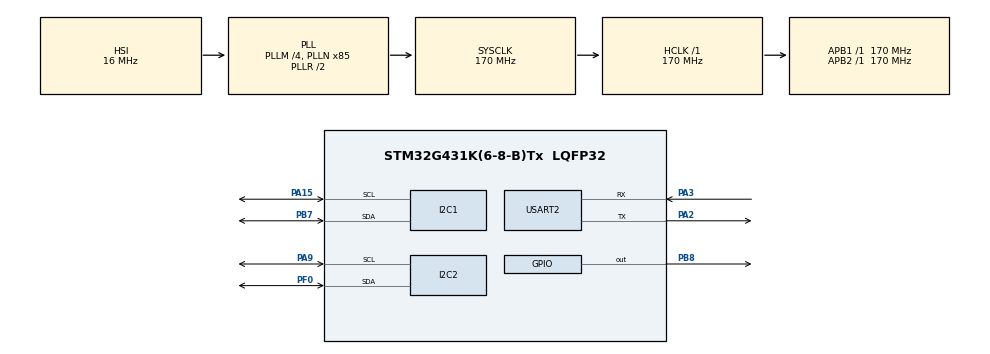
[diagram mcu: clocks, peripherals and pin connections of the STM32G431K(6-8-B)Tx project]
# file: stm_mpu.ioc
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I2C1.Timing=0x40B285C2
I2C2.Timing=0x40B285C2
Mcu.Family=STM32G4
Mcu.Name=STM32G431K(6-8-B)Tx
Mcu.Package=LQFP32
NUCLEO-G431KB.LD2=true
NUCLEO-G431KB.VCP=true
NVIC.PriorityGroup=NVIC_PRIORITYGROUP_4
PA13.GPIO_Label=T_SWDIO
PA13.Signal=SYS_JTMS-SWDIO
PA14.GPIO_Label=T_SWCLK
PA14.Signal=SYS_JTCK-SWCLK
PA15.Mode=I2C
PA15.Signal=I2C1_SCL
PA2.Mode=Asynchronous
PA2.Signal=USART2_TX
PA3.Mode=Asynchronous
PA3.Signal=USART2_RX
PA9.Mode=I2C
PA9.Signal=I2C2_SCL
PB3.GPIO_Label=T_SWO
PB3.Signal=SYS_JTDO-SWO
PB7.Mode=I2C
PB7.Signal=I2C1_SDA
PB8-BOOT0.Signal=GPIO_Output
PF0-OSC_IN.Mode=I2C
PF0-OSC_IN.Signal=I2C2_SDA
ProjectManager.HeapSize=0x200
ProjectManager.StackSize=0x400
ProjectManager.TargetToolchain=STM32CubeIDE
RCC.ADC12Freq_Value=170000000
RCC.AHBFreq_Value=170000000
RCC.APB1Freq_Value=170000000
RCC.APB1TimFreq_Value=170000000
RCC.APB2Freq_Value=170000000
RCC.APB2TimFreq_Value=170000000
RCC.CortexFreq_Value=170000000
RCC.EXTERNAL_CLOCK_VALUE=12288000
RCC.HCLKFreq_Value=170000000
RCC.HSE_VALUE=8000000
RCC.HSI48_VALUE=48000000
RCC.HSI_VALUE=16000000
RCC.LSE_VALUE=32768
RCC.PLLM=RCC_PLLM_DIV4
RCC.PLLN=85
RCC.SYSCLKFreq_VALUE=170000000
RCC.SYSCLKSource=RCC_SYSCLKSOURCE_PLLCLK
RCC.USBFreq_Value=170000000
RCC.VCOOutputFreq_Value=340000000
USART2.VirtualMode-Asynchronous=VM_ASYNC
VP_NUCLEO-G431KB_VS_BSP_COMMON.Mode=COMMON
VP_SYS_VS_DBSignals.Mode=DisableDeadBatterySignals
board=NUCLEO-G431KB

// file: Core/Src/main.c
/* USER CODE BEGIN Header */
/**
  ******************************************************************************
  * @file           : main.c
  * @brief          : Main program body
  ******************************************************************************
  * @attention
  *
  * Copyright (c) 2025 STMicroelectronics.
  * All rights reserved.
  *
  * This software is licensed under terms that can be found in the LICENSE file
  * in the root directory of this software component.
  * If no LICENSE file comes with this software, it is provided AS-IS.
  *
  ******************************************************************************
  */
/* USER CODE END Header */
#include "main.h"

/* USER CODE BEGIN Includes */
#include<MPU6050.h>
/* USER CODE END Includes */

I2C_HandleTypeDef hi2c1;
I2C_HandleTypeDef hi2c2;

UART_HandleTypeDef huart2;

void SystemClock_Config(void);
static void MX_GPIO_Init(void);
static void MX_I2C1_Init(void);
static void MX_I2C2_Init(void);
static void MX_USART2_UART_Init(void);

int main(void)
{

  /* MCU Configuration--------------------------------------------------------*/

  /* Reset of all peripherals, Initializes the Flash interface and the Systick. */
  HAL_Init();

  /* Configure the system clock */
  SystemClock_Config();

  /* Initialize all configured peripherals */
  MX_GPIO_Init();
  MX_I2C1_Init();
  MX_I2C2_Init();
  MX_USART2_UART_Init();

  /* Initialize leds */
  BSP_LED_Init(LED_GREEN);

  MPU6050_Initialization();

  /* Infinite loop */
  while (1)
  {
	    char buffer[100];  // Buffer to hold the formatted string
		MPU6050_ProcessData(&MPU6050);

	    // Format the data into a string
	    snprintf(buffer, sizeof(buffer), "%d, %d, %d\n",
	    		MPU6050.acc_x_raw, MPU6050.acc_y_raw, MPU6050.acc_z_raw);

	    // Send the string over UART
	    HAL_UART_Transmit(&huart2, (uint8_t*)buffer, strlen(buffer), HAL_MAX_DELAY);
	    HAL_Delay(50);
  }
}

void SystemClock_Config(void)
{
  RCC_OscInitTypeDef RCC_OscInitStruct = {0};
  RCC_ClkInitTypeDef RCC_ClkInitStruct = {0};

  /** Configure the main internal regulator output voltage
  */
  HAL_PWREx_ControlVoltageScaling(PWR_REGULATOR_VOLTAGE_SCALE1_BOOST);

  /** Initializes the RCC Oscillators according to the specified parameters
  * in the RCC_OscInitTypeDef structure.
  */
  RCC_OscInitStruct.OscillatorType = RCC_OSCILLATORTYPE_HSI;
  RCC_OscInitStruct.HSIState = RCC_HSI_ON;
  RCC_OscInitStruct.HSICalibrationValue = RCC_HSICALIBRATION_DEFAULT;
  RCC_OscInitStruct.PLL.PLLState = RCC_PLL_ON;
  RCC_OscInitStruct.PLL.PLLSource = RCC_PLLSOURCE_HSI;
  RCC_OscInitStruct.PLL.PLLM = RCC_PLLM_DIV4;
  RCC_OscInitStruct.PLL.PLLN = 85;
  RCC_OscInitStruct.PLL.PLLP = RCC_PLLP_DIV2;
  RCC_OscInitStruct.PLL.PLLQ = RCC_PLLQ_DIV2;
  RCC_OscInitStruct.PLL.PLLR = RCC_PLLR_DIV2;
  if (HAL_RCC_OscConfig(&RCC_OscInitStruct) != HAL_OK)
  {
    Error_Handler();
  }

  /** Initializes the CPU, AHB and APB buses clocks
  */
  RCC_ClkInitStruct.ClockType = RCC_CLOCKTYPE_HCLK|RCC_CLOCKTYPE_SYSCLK
                              |RCC_CLOCKTYPE_PCLK1|RCC_CLOCKTYPE_PCLK2;
  RCC_ClkInitStruct.SYSCLKSource = RCC_SYSCLKSOURCE_PLLCLK;
  RCC_ClkInitStruct.AHBCLKDivider = RCC_SYSCLK_DIV1;
  RCC_ClkInitStruct.APB1CLKDivider = RCC_HCLK_DIV1;
  RCC_ClkInitStruct.APB2CLKDivider = RCC_HCLK_DIV1;

  if (HAL_RCC_ClockConfig(&RCC_ClkInitStruct, FLASH_LATENCY_4) != HAL_OK)
  {
    Error_Handler();
  }
}

static void MX_I2C1_Init(void)
{

  hi2c1.Instance = I2C1;
  hi2c1.Init.Timing = 0x40B285C2;
  hi2c1.Init.OwnAddress1 = 0;
  hi2c1.Init.AddressingMode = I2C_ADDRESSINGMODE_7BIT;
  hi2c1.Init.DualAddressMode = I2C_DUALADDRESS_DISABLE;
  hi2c1.Init.OwnAddress2 = 0;
  hi2c1.Init.OwnAddress2Masks = I2C_OA2_NOMASK;
  hi2c1.Init.GeneralCallMode = I2C_GENERALCALL_DISABLE;
  hi2c1.Init.NoStretchMode = I2C_NOSTRETCH_DISABLE;
  if (HAL_I2C_Init(&hi2c1) != HAL_OK)
  {
    Error_Handler();
  }

  /** Configure Analogue filter
  */
  if (HAL_I2CEx_ConfigAnalogFilter(&hi2c1, I2C_ANALOGFILTER_ENABLE) != HAL_OK)
  {
    Error_Handler();
  }

  /** Configure Digital filter
  */
  if (HAL_I2CEx_ConfigDigitalFilter(&hi2c1, 0) != HAL_OK)
  {
    Error_Handler();
  }

}

static void MX_I2C2_Init(void)
{

  hi2c2.Instance = I2C2;
  hi2c2.Init.Timing = 0x40B285C2;
  hi2c2.Init.OwnAddress1 = 0;
  hi2c2.Init.AddressingMode = I2C_ADDRESSINGMODE_7BIT;
  hi2c2.Init.DualAddressMode = I2C_DUALADDRESS_DISABLE;
  hi2c2.Init.OwnAddress2 = 0;
  hi2c2.Init.OwnAddress2Masks = I2C_OA2_NOMASK;
  hi2c2.Init.GeneralCallMode = I2C_GENERALCALL_DISABLE;
  hi2c2.Init.NoStretchMode = I2C_NOSTRETCH_DISABLE;
  if (HAL_I2C_Init(&hi2c2) != HAL_OK)
  {
    Error_Handler();
  }

  /** Configure Analogue filter
  */
  if (HAL_I2CEx_ConfigAnalogFilter(&hi2c2, I2C_ANALOGFILTER_ENABLE) != HAL_OK)
  {
    Error_Handler();
  }

  /** Configure Digital filter
  */
  if (HAL_I2CEx_ConfigDigitalFilter(&hi2c2, 0) != HAL_OK)
  {
    Error_Handler();
  }

}

static void MX_USART2_UART_Init(void)
{

  huart2.Instance = USART2;
  huart2.Init.BaudRate = 115200;
  huart2.Init.WordLength = UART_WORDLENGTH_8B;
  huart2.Init.StopBits = UART_STOPBITS_1;
  huart2.Init.Parity = UART_PARITY_NONE;
  huart2.Init.Mode = UART_MODE_TX_RX;
  huart2.Init.HwFlowCtl = UART_HWCONTROL_NONE;
  huart2.Init.OverSampling = UART_OVERSAMPLING_16;
  huart2.Init.OneBitSampling = UART_ONE_BIT_SAMPLE_DISABLE;
  huart2.Init.ClockPrescaler = UART_PRESCALER_DIV1;
  huart2.AdvancedInit.AdvFeatureInit = UART_ADVFEATURE_NO_INIT;
  if (HAL_UART_Init(&huart2) != HAL_OK)
  {
    Error_Handler();
  }
  if (HAL_UARTEx_SetTxFifoThreshold(&huart2, UART_TXFIFO_THRESHOLD_1_8) != HAL_OK)
  {
    Error_Handler();
  }
  if (HAL_UARTEx_SetRxFifoThreshold(&huart2, UART_RXFIFO_THRESHOLD_1_8) != HAL_OK)
  {
    Error_Handler();
  }
  if (HAL_UARTEx_DisableFifoMode(&huart2) != HAL_OK)
  {
    Error_Handler();
  }

}

static void MX_GPIO_Init(void)
{

  /* GPIO Ports Clock Enable */
  __HAL_RCC_GPIOF_CLK_ENABLE();
  __HAL_RCC_GPIOA_CLK_ENABLE();
  __HAL_RCC_GPIOB_CLK_ENABLE();

}

/* USER CODE BEGIN Header */
/**
  ******************************************************************************
  * @file           : main.c
  * @brief          : Main program body
  ******************************************************************************
  * @attention
  *
  * Copyright (c) 2025 STMicroelectronics.
  * All rights reserved.
  *
  * This software is licensed under terms that can be found in the LICENSE file
  * in the root directory of this software component.
  * If no LICENSE file comes with this software, it is provided AS-IS.
  *
  ******************************************************************************
  */
/* USER CODE END Header */

void Error_Handler(void)
{
  __disable_irq();
  while (1)
  {
  }
}
